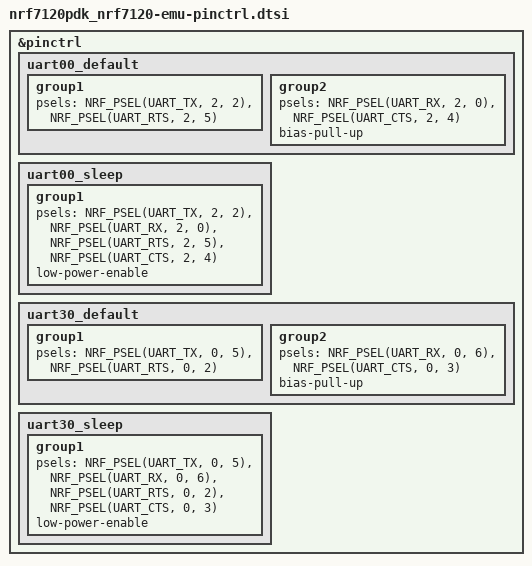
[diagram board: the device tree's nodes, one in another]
/*
 * Copyright (c) 2025 Nordic Semiconductor
 * SPDX-License-Identifier: LicenseRef-Nordic-5-Clause
 */

&pinctrl {
	/omit-if-no-ref/ uart00_default: uart00_default {
		group1 {
			psels = <NRF_PSEL(UART_TX, 2, 2)>,
					<NRF_PSEL(UART_RTS, 2, 5)>;
		};

		group2 {
			psels = <NRF_PSEL(UART_RX, 2, 0)>,
					<NRF_PSEL(UART_CTS, 2, 4)>;
			bias-pull-up;
		};
	};

	/omit-if-no-ref/ uart00_sleep: uart00_sleep {
		group1 {
			psels = <NRF_PSEL(UART_TX, 2, 2)>,
					<NRF_PSEL(UART_RX, 2, 0)>,
					<NRF_PSEL(UART_RTS, 2, 5)>,
					<NRF_PSEL(UART_CTS, 2, 4)>;
			low-power-enable;
		};
	};
	
	/omit-if-no-ref/ uart30_default: uart30_default {
		group1 {
			psels = <NRF_PSEL(UART_TX, 0, 5)>,
				<NRF_PSEL(UART_RTS, 0, 2)>;
		};

		group2 {
			psels = <NRF_PSEL(UART_RX, 0, 6)>,
				<NRF_PSEL(UART_CTS, 0, 3)>;
			bias-pull-up;
		};
	};

	/omit-if-no-ref/ uart30_sleep: uart30_sleep {
		group1 {
			psels = <NRF_PSEL(UART_TX, 0, 5)>,
				<NRF_PSEL(UART_RX, 0, 6)>,
				<NRF_PSEL(UART_RTS, 0, 2)>,
				<NRF_PSEL(UART_CTS, 0, 3)>;
			low-power-enable;
		};
	};
};



